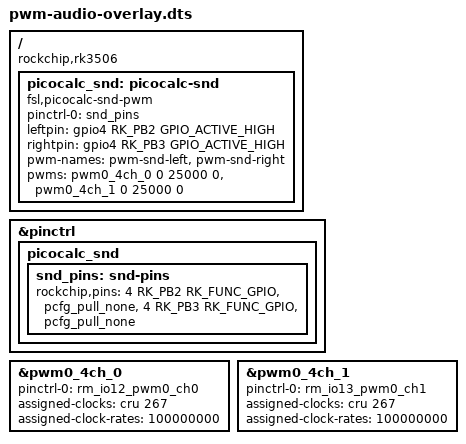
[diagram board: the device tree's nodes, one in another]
/dts-v1/;
/plugin/;

#include <dt-bindings/pinctrl/rockchip.h>
#include <dt-bindings/gpio/gpio.h>

/*
 * Device tree overlay for PicoCalc hardware PWM sound
 *
 * Enables the fsl,picocalc-snd-pwm sound device using PWM channels 0 and 1
 * (RM_IO12, RM_IO13). Requires a hardware mod; do not load together with
 * m0-audio overlay (same pins, different use).
 *
 * To apply at runtime:
 *   mkdir -p /sys/kernel/config/device-tree/overlays/pwm-audio
 *   cat /lib/firmware/overlays/pwm-audio.dtbo > /sys/kernel/config/device-tree/overlays/pwm-audio/dtbo
 *   echo 1 > /sys/kernel/config/device-tree/overlays/pwm-audio/status
 *
 * To remove:
 *   echo 0 > /sys/kernel/config/device-tree/overlays/pwm-audio/status
 *   rmdir /sys/kernel/config/device-tree/overlays/pwm-audio
 */

/ {
    compatible = "rockchip,rk3506";

    fragment@0 {
        target-path = "/";
        __overlay__ {
            picocalc_snd: picocalc-snd {
                status = "okay";
                compatible = "fsl,picocalc-snd-pwm";
                pinctrl-names = "default";
                pinctrl-0 = <&snd_pins>;
                leftpin = <&gpio4 RK_PB2 GPIO_ACTIVE_HIGH>;
                rightpin = <&gpio4 RK_PB3 GPIO_ACTIVE_HIGH>;
                pwm-names = "pwm-snd-left", "pwm-snd-right";
                pwms = <&pwm0_4ch_0 0 25000 0>, <&pwm0_4ch_1 0 25000 0>;
            };
        };
    };

    fragment@1 {
        target = <&pinctrl>;
        __overlay__ {
            picocalc_snd {
                snd_pins: snd-pins {
                    rockchip,pins =
                        <4 RK_PB2 RK_FUNC_GPIO &pcfg_pull_none>,
                        <4 RK_PB3 RK_FUNC_GPIO &pcfg_pull_none>;
                };
            };
        };
    };

    fragment@2 {
        target = <&pwm0_4ch_0>;
        __overlay__ {
            pinctrl-names = "active";
            pinctrl-0 = <&rm_io12_pwm0_ch0>;
            status = "okay";
            assigned-clocks = <&cru 267>;
            assigned-clock-rates = <100000000>;
        };
    };

    fragment@3 {
        target = <&pwm0_4ch_1>;
        __overlay__ {
            pinctrl-names = "active";
            pinctrl-0 = <&rm_io13_pwm0_ch1>;
            status = "okay";
            assigned-clocks = <&cru 267>;
            assigned-clock-rates = <100000000>;
        };
    };
};
